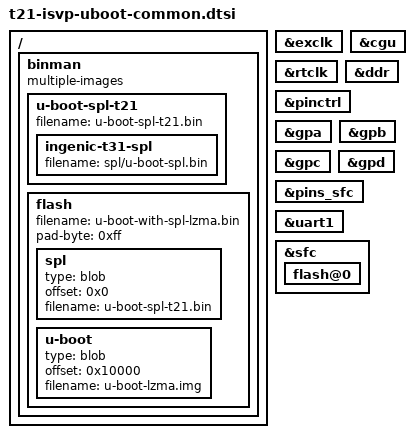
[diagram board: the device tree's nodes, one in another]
// SPDX-License-Identifier: GPL-2.0+
/*
 * Shared U-Boot overlay for the Ingenic ISVP-T21 SFC-NOR leaf DTs.
 * Each per-SKU <leaf>-u-boot.dtsi is a one-line include of this file.
 *
 * Provides the binman image description for the SFC-NOR boot. The T21
 * mask ROM SFC-NOR boot path is the common XBurst1 one (the 2 KiB
 * header CRC7+length finalized by the ingenic-t31-spl binman etype -
 * that header format is family-generic, emitted by the shared
 * start.S, not T31-specific):
 *
 *   u-boot-spl-t21.bin       : SPL with the finalized boot header.
 *   u-boot-with-spl-lzma.bin : headered SPL at offset 0 and LZMA
 *                              U-Boot at the SPL-loader offset.
 *
 * Also tags the SPL-needed nodes bootph-all so they survive into the
 * SPL devicetree: the SPL probes the DDR node (UCLASS_RAM) and loads
 * U-Boot proper from NOR via the DM SFC driver.
 */

/ {
	binman: binman {
		multiple-images;
	};
};

&binman {
	u-boot-spl-t21 {
		filename = "u-boot-spl-t21.bin";

		ingenic-t31-spl {
			filename = "spl/u-boot-spl.bin";
		};
	};

	flash {
		filename = "u-boot-with-spl-lzma.bin";
		pad-byte = <0xff>;

		spl {
			type = "blob";
			offset = <0x0>;
			filename = "u-boot-spl-t21.bin";
		};

		u-boot {
			type = "blob";
			offset = <0x10000>;
			filename = "u-boot-lzma.img";
		};
	};
};

&exclk { bootph-all; };
&rtclk { bootph-all; };
&cgu { bootph-all; };
&ddr { bootph-all; };		/* per-SKU compatible set by the leaf .dts */
&pinctrl { bootph-all; };
&gpa { bootph-all; };
&gpb { bootph-all; };
&gpc { bootph-all; };
&gpd { bootph-all; };
&pins_sfc { bootph-all; };
&uart1 { bootph-all; };
&sfc {
	bootph-all;
	flash@0 {
		bootph-all;
	};
};
